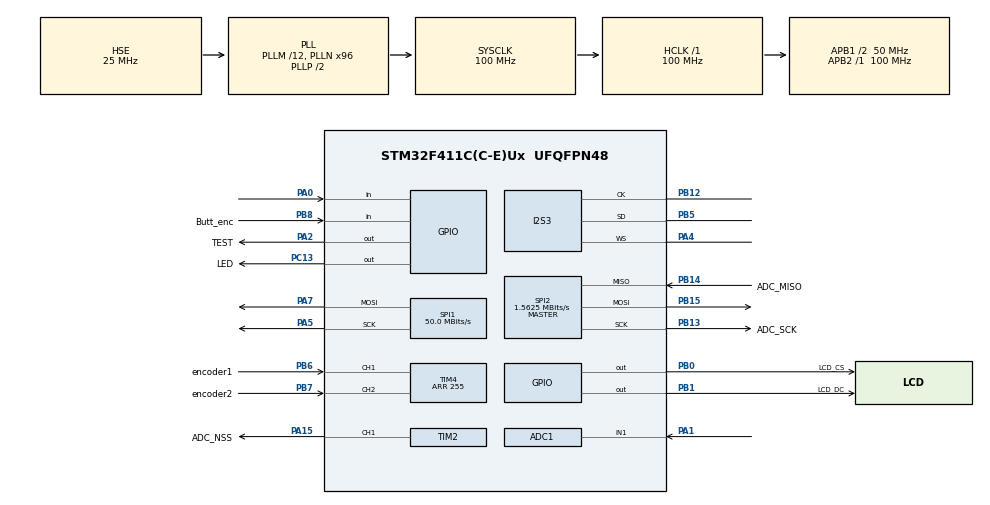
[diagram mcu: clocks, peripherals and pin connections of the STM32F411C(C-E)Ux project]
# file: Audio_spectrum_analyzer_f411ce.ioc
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ADC1.Channel-0\#ChannelRegularConversion=ADC_CHANNEL_1
ADC1.ExternalTrigConv=ADC_EXTERNALTRIGCONV_T2_TRGO
ADC1.InjNumberOfConversion=0
ADC1.NbrOfConversionFlag=1
ADC1.Rank-0\#ChannelRegularConversion=1
ADC1.SamplingTime-0\#ChannelRegularConversion=ADC_SAMPLETIME_3CYCLES
ADC1.master=1
Dma.ADC1.3.Direction=DMA_PERIPH_TO_MEMORY
Dma.ADC1.3.FIFOMode=DMA_FIFOMODE_DISABLE
Dma.ADC1.3.Instance=DMA2_Stream0
Dma.ADC1.3.MemDataAlignment=DMA_MDATAALIGN_HALFWORD
Dma.ADC1.3.MemInc=DMA_MINC_ENABLE
Dma.ADC1.3.Mode=DMA_NORMAL
Dma.ADC1.3.PeriphDataAlignment=DMA_PDATAALIGN_HALFWORD
Dma.ADC1.3.PeriphInc=DMA_PINC_DISABLE
Dma.ADC1.3.Priority=DMA_PRIORITY_LOW
Dma.Request0=SPI1_TX
Dma.Request1=SPI2_RX
Dma.Request2=TIM2_CH3/UP
Dma.Request3=ADC1
Dma.Request4=SPI3_RX
Dma.SPI1_TX.0.Direction=DMA_MEMORY_TO_PERIPH
Dma.SPI1_TX.0.FIFOMode=DMA_FIFOMODE_DISABLE
Dma.SPI1_TX.0.Instance=DMA2_Stream2
Dma.SPI1_TX.0.MemDataAlignment=DMA_MDATAALIGN_HALFWORD
Dma.SPI1_TX.0.MemInc=DMA_MINC_ENABLE
Dma.SPI1_TX.0.Mode=DMA_NORMAL
Dma.SPI1_TX.0.PeriphDataAlignment=DMA_PDATAALIGN_HALFWORD
Dma.SPI1_TX.0.PeriphInc=DMA_PINC_DISABLE
Dma.SPI1_TX.0.Priority=DMA_PRIORITY_LOW
Dma.SPI2_RX.1.Direction=DMA_PERIPH_TO_MEMORY
Dma.SPI2_RX.1.FIFOMode=DMA_FIFOMODE_DISABLE
Dma.SPI2_RX.1.Instance=DMA1_Stream3
Dma.SPI2_RX.1.MemDataAlignment=DMA_MDATAALIGN_HALFWORD
Dma.SPI2_RX.1.MemInc=DMA_MINC_ENABLE
Dma.SPI2_RX.1.Mode=DMA_CIRCULAR
Dma.SPI2_RX.1.PeriphDataAlignment=DMA_PDATAALIGN_HALFWORD
Dma.SPI2_RX.1.PeriphInc=DMA_PINC_DISABLE
Dma.SPI2_RX.1.Priority=DMA_PRIORITY_LOW
Dma.SPI3_RX.4.Direction=DMA_PERIPH_TO_MEMORY
Dma.SPI3_RX.4.FIFOMode=DMA_FIFOMODE_DISABLE
Dma.SPI3_RX.4.Instance=DMA1_Stream0
Dma.SPI3_RX.4.MemDataAlignment=DMA_MDATAALIGN_HALFWORD
Dma.SPI3_RX.4.MemInc=DMA_MINC_ENABLE
Dma.SPI3_RX.4.Mode=DMA_CIRCULAR
Dma.SPI3_RX.4.PeriphDataAlignment=DMA_PDATAALIGN_HALFWORD
Dma.SPI3_RX.4.PeriphInc=DMA_PINC_DISABLE
Dma.SPI3_RX.4.Priority=DMA_PRIORITY_LOW
Dma.TIM2_CH3/UP.2.Direction=DMA_MEMORY_TO_PERIPH
Dma.TIM2_CH3/UP.2.FIFOMode=DMA_FIFOMODE_DISABLE
Dma.TIM2_CH3/UP.2.Instance=DMA1_Stream1
Dma.TIM2_CH3/UP.2.MemDataAlignment=DMA_MDATAALIGN_HALFWORD
Dma.TIM2_CH3/UP.2.MemInc=DMA_MINC_ENABLE
Dma.TIM2_CH3/UP.2.Mode=DMA_CIRCULAR
Dma.TIM2_CH3/UP.2.PeriphDataAlignment=DMA_PDATAALIGN_HALFWORD
Dma.TIM2_CH3/UP.2.PeriphInc=DMA_PINC_DISABLE
Dma.TIM2_CH3/UP.2.Priority=DMA_PRIORITY_LOW
I2S3.AudioFreq=I2S_AUDIOFREQ_8K
I2S3.DataFormat=I2S_DATAFORMAT_24B
I2S3.ErrorAudioFreq=-0.01 %
I2S3.FullDuplexMode=I2S_FULLDUPLEXMODE_DISABLE
I2S3.Instance=SPI$Index
I2S3.Mode=I2S_MODE_MASTER_RX
I2S3.RealAudioFreq=7.999 KHz
I2S3.Standard=I2S_STANDARD_PHILIPS
I2S3.VirtualMode=I2S_MODE_MASTER
Mcu.Family=STM32F4
Mcu.Name=STM32F411C(C-E)Ux
Mcu.Package=UFQFPN48
NVIC.DMA1_Stream0_IRQn=true\:0\:0\:false\:false\:true\:false\:true
NVIC.DMA1_Stream1_IRQn=true\:0\:0\:false\:false\:true\:false\:true
NVIC.DMA1_Stream3_IRQn=true\:0\:0\:false\:false\:true\:false\:true
NVIC.DMA2_Stream0_IRQn=true\:0\:0\:false\:false\:true\:false\:true
NVIC.DMA2_Stream2_IRQn=true\:0\:0\:false\:false\:true\:false\:true
NVIC.PriorityGroup=NVIC_PRIORITYGROUP_4
NVIC.SPI1_IRQn=true\:1\:0\:true\:false\:true\:true\:true
NVIC.TIM1_TRG_COM_TIM11_IRQn=true\:0\:0\:false\:false\:true\:true\:true
NVIC.TIM1_UP_TIM10_IRQn=true\:15\:0\:false\:false\:true\:false\:true
NVIC.TIM2_IRQn=true\:0\:0\:false\:false\:true\:true\:true
NVIC.TimeBase=TIM1_UP_TIM10_IRQn
NVIC.TimeBaseIP=TIM10
PA0-WKUP.Signal=GPIO_Input
PA1.Signal=ADCx_IN1
PA13.Mode=Serial_Wire
PA13.Signal=SYS_JTMS-SWDIO
PA14.Mode=Serial_Wire
PA14.Signal=SYS_JTCK-SWCLK
PA15.GPIO_Label=ADC_NSS
PA15.Signal=S_TIM2_CH1_ETR
PA2.GPIO_Label=TEST
PA2.GPIO_Speed=GPIO_SPEED_FREQ_VERY_HIGH
PA2.Signal=GPIO_Output
PA4.GPIO_PuPd=GPIO_NOPULL
PA4.GPIO_Speed=GPIO_SPEED_FREQ_LOW
PA4.Mode=Half_Duplex_Master
PA4.Signal=I2S3_WS
PA5.GPIO_PuPd=GPIO_PULLUP
PA5.Mode=TX_Only_Simplex_Unidirect_Master
PA5.Signal=SPI1_SCK
PA7.GPIO_PuPd=GPIO_PULLUP
PA7.Mode=TX_Only_Simplex_Unidirect_Master
PA7.Signal=SPI1_MOSI
PB0.GPIO_Label=LCD_CS
PB0.GPIO_PuPd=GPIO_PULLUP
PB0.GPIO_Speed=GPIO_SPEED_FREQ_VERY_HIGH
PB0.PinState=GPIO_PIN_SET
PB0.Signal=GPIO_Output
PB1.GPIO_Label=LCD_DC
PB1.GPIO_PuPd=GPIO_PULLUP
PB1.GPIO_Speed=GPIO_SPEED_FREQ_VERY_HIGH
PB1.PinState=GPIO_PIN_SET
PB1.Signal=GPIO_Output
PB12.GPIO_Speed=GPIO_SPEED_FREQ_VERY_HIGH
PB12.Mode=Half_Duplex_Master
PB12.Signal=I2S3_CK
PB13.GPIO_Label=ADC_SCK
PB13.GPIO_PuPd=GPIO_PULLUP
PB13.Mode=Full_Duplex_Master
PB13.Signal=SPI2_SCK
PB14.GPIO_Label=ADC_MISO
PB14.GPIO_PuPd=GPIO_PULLUP
PB14.Mode=Full_Duplex_Master
PB14.Signal=SPI2_MISO
PB15.Mode=Full_Duplex_Master
PB15.Signal=SPI2_MOSI
PB5.GPIO_PuPd=GPIO_PULLDOWN
PB5.GPIO_Speed=GPIO_SPEED_FREQ_VERY_HIGH
PB5.Mode=Half_Duplex_Master
PB5.Signal=I2S3_SD
PB6.GPIO_Label=encoder1
PB6.Signal=S_TIM4_CH1
PB7.GPIO_Label=encoder2
PB7.Signal=S_TIM4_CH2
PB8.GPIO_Label=Butt_enc
PB8.GPIO_PuPd=GPIO_PULLUP
PB8.Signal=GPIO_Input
PC13-ANTI_TAMP.GPIO_Label=LED
PC13-ANTI_TAMP.Signal=GPIO_Output
PH0\ -\ OSC_IN.Mode=HSE-External-Oscillator
PH0\ -\ OSC_IN.Signal=RCC_OSC_IN
PH1\ -\ OSC_OUT.Mode=HSE-External-Oscillator
PH1\ -\ OSC_OUT.Signal=RCC_OSC_OUT
ProjectManager.HeapSize=0x400
ProjectManager.StackSize=0x800
ProjectManager.TargetToolchain=STM32CubeIDE
RCC.48MHZClocksFreq_Value=50000000
RCC.AHBFreq_Value=100000000
RCC.APB1CLKDivider=RCC_HCLK_DIV2
RCC.APB1Freq_Value=50000000
RCC.APB1TimFreq_Value=100000000
RCC.APB2Freq_Value=100000000
RCC.APB2TimFreq_Value=100000000
RCC.CortexFreq_Value=100000000
RCC.HCLKFreq_Value=100000000
RCC.HSE_VALUE=25000000
RCC.HSI_VALUE=16000000
RCC.LSE_VALUE=32768
RCC.PLLM=12
RCC.PLLN=96
RCC.PLLSourceVirtual=RCC_PLLSOURCE_HSE
RCC.SYSCLKFreq_VALUE=100000000
RCC.SYSCLKSource=RCC_SYSCLKSOURCE_PLLCLK
RCC.VCOOutputFreq_Value=200000000
SH.ADCx_IN1.0=ADC1_IN1,IN1
SH.S_TIM2_CH1_ETR.0=TIM2_CH1,PWM Generation1 CH1
SH.S_TIM4_CH1.0=TIM4_CH1,Encoder_Interface
SH.S_TIM4_CH2.0=TIM4_CH2,Encoder_Interface
SPI1.BaudRatePrescaler=SPI_BAUDRATEPRESCALER_2
SPI1.CalculateBaudRate=50.0 MBits/s
SPI1.Direction=SPI_DIRECTION_2LINES
SPI1.Mode=SPI_MODE_MASTER
SPI1.VirtualType=VM_MASTER
SPI2.BaudRatePrescaler=SPI_BAUDRATEPRESCALER_32
SPI2.CalculateBaudRate=1.5625 MBits/s
SPI2.DataSize=SPI_DATASIZE_16BIT
SPI2.Direction=SPI_DIRECTION_2LINES
SPI2.Mode=SPI_MODE_MASTER
SPI2.VirtualType=VM_MASTER
TIM11.Period=9
TIM11.Prescaler=999
TIM2.Channel-PWM\ Generation1\ CH1=TIM_CHANNEL_1
TIM2.OCPolarity_1=TIM_OCPOLARITY_LOW
TIM2.Period=5000-1
TIM2.Pulse-PWM\ Generation1\ CH1=1100
TIM2.TIM_MasterOutputTrigger=TIM_TRGO_UPDATE
TIM4.Period=255
VP_SYS_VS_tim10.Mode=TIM10
VP_TIM11_VS_ClockSourceINT.Mode=Enable_Timer
VP_TIM2_VS_ClockSourceINT.Mode=Internal
board=custom

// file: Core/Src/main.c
/* USER CODE BEGIN Header
 *
 *  tim2 - trigger timer for all ADC (generates CS for external ADC on PWM pin)
 *	SPI1 - for display ST7789
 *	SPI2 - for external ADC
 *	DMA2_Stream0 - ADC0: periph - memory
 *	DMA2_Stream2 - SPI1_TX: memory - display
 *	DMA1_Stream1 - TIM2_Update: memory - SPI2_TX external ADC
 *	DMA1_Stream3 - SPI2_RX: external ADC - memory
 *	DMA2_Stream7 - UART1_TX: memory - UART
 *
 */
/* USER CODE END Header */
#include "main.h"
#include "adc.h"
#include "dma.h"
#include "i2s.h"
#include "spi.h"
#include "tim.h"
#include "gpio.h"

/* USER CODE BEGIN Includes */
#include "analyzer.h"
#include "st7789.h"
#include "stdio.h"
/* USER CODE END Includes */

/* USER CODE BEGIN PV */
extern volatile unsigned long ulHighFrequencyTimerTicks;
/* USER CODE END PV */

void SystemClock_Config(void);

int main(void)
{

  /* MCU Configuration--------------------------------------------------------*/

  /* Reset of all peripherals, Initializes the Flash interface and the Systick. */
  HAL_Init();

  /* Configure the system clock */
  SystemClock_Config();

  /* Initialize all configured peripherals */
  MX_GPIO_Init();
  MX_DMA_Init();
  MX_TIM2_Init();
  MX_SPI1_Init();
  MX_SPI2_Init();
  MX_TIM4_Init();
  MX_TIM11_Init();
  MX_ADC1_Init();
  MX_I2S3_Init();
  /* USER CODE BEGIN 2 */

	ST7789_Init(&hspi1);
	RTOSstart();

  /* USER CODE END 2 */

  /* Infinite loop */
	while (1)
	{

	}
}

void SystemClock_Config(void)
{
  RCC_OscInitTypeDef RCC_OscInitStruct = {0};
  RCC_ClkInitTypeDef RCC_ClkInitStruct = {0};

  /** Configure the main internal regulator output voltage
  */
  __HAL_RCC_PWR_CLK_ENABLE();
  __HAL_PWR_VOLTAGESCALING_CONFIG(PWR_REGULATOR_VOLTAGE_SCALE1);
  /** Initializes the RCC Oscillators according to the specified parameters
  * in the RCC_OscInitTypeDef structure.
  */
  RCC_OscInitStruct.OscillatorType = RCC_OSCILLATORTYPE_HSE;
  RCC_OscInitStruct.HSEState = RCC_HSE_ON;
  RCC_OscInitStruct.PLL.PLLState = RCC_PLL_ON;
  RCC_OscInitStruct.PLL.PLLSource = RCC_PLLSOURCE_HSE;
  RCC_OscInitStruct.PLL.PLLM = 12;
  RCC_OscInitStruct.PLL.PLLN = 96;
  RCC_OscInitStruct.PLL.PLLP = RCC_PLLP_DIV2;
  RCC_OscInitStruct.PLL.PLLQ = 4;
  if (HAL_RCC_OscConfig(&RCC_OscInitStruct) != HAL_OK)
  {
    Error_Handler();
  }
  /** Initializes the CPU, AHB and APB buses clocks
  */
  RCC_ClkInitStruct.ClockType = RCC_CLOCKTYPE_HCLK|RCC_CLOCKTYPE_SYSCLK
                              |RCC_CLOCKTYPE_PCLK1|RCC_CLOCKTYPE_PCLK2;
  RCC_ClkInitStruct.SYSCLKSource = RCC_SYSCLKSOURCE_PLLCLK;
  RCC_ClkInitStruct.AHBCLKDivider = RCC_SYSCLK_DIV1;
  RCC_ClkInitStruct.APB1CLKDivider = RCC_HCLK_DIV2;
  RCC_ClkInitStruct.APB2CLKDivider = RCC_HCLK_DIV1;

  if (HAL_RCC_ClockConfig(&RCC_ClkInitStruct, FLASH_LATENCY_3) != HAL_OK)
  {
    Error_Handler();
  }
}

/* USER CODE BEGIN 4 */

int __io_putchar(int ch)
{
	ITM_SendChar(ch);
	return ch;
}

/* USER CODE END 4 */

void HAL_TIM_PeriodElapsedCallback(TIM_HandleTypeDef *htim)
{
  if (htim->Instance == TIM10) {
    HAL_IncTick();
  }
  /* USER CODE BEGIN Callback 1 */
	if (htim->Instance == TIM11)
	{
		ulHighFrequencyTimerTicks++;
	}
  /* USER CODE END Callback 1 */
}

void Error_Handler(void)
{
	__disable_irq();
	while (1)
	{
	}
}

/************************ (C) COPYRIGHT STMicroelectronics *****END OF FILE****/
